# MCXC444 register map
Vendor: NXP Semiconductors; Series: MCX; File version: 1.6
CPU: CM0PLUS r0p0, little endian, no MPU, no FPU, VTOR, 2 interrupt priority bits
Registers are 32-bit, read-write, reset 0x0 unless marked. A register's access mark holds for its fields unless they carry their own. Offsets are from the block's base; [hi:lo] are bit positions; {n}, {i} and the like mark numbered series; 'fields as' and 'values as' point back to an identical list.

## LCD — Segment Liquid Crystal Display
Base 0x40053000; register names take the prefix LCD_
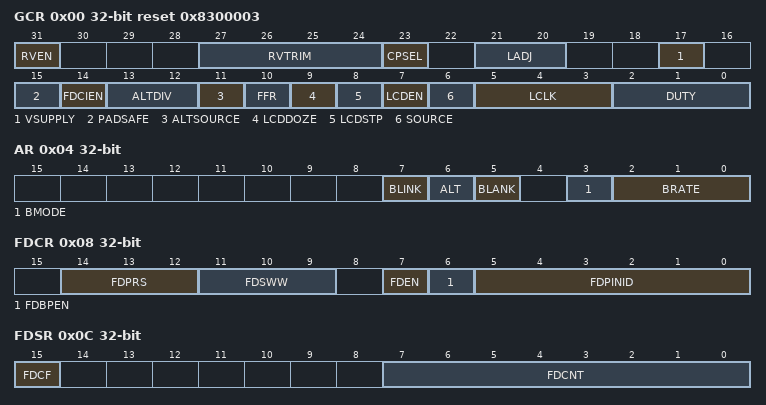
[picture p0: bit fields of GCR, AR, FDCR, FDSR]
0x00 GCR reset 0x8300003 — LCD General Control Register
  [31] RVEN — Regulated Voltage Enable
    0=b0 (Regulated voltage disabled.); 1=b1 (Regulated voltage enabled.)
  [27:24] RVTRIM — Regulated Voltage Trim
  [23] CPSEL — Charge Pump or Resistor Bias Select
    0=b0 (LCD charge pump is disabled. Resistor network selected. (The internal 1/3-bias is forced.)); 1=b1 (LCD charge pump is selected. Resistor network disabled. (The internal 1/3-bias is forced.))
  [21:20] LADJ — Load Adjust
  [17] VSUPPLY — Voltage Supply Control
    0=b0 (Drive VLL3 internally from VDD); 1=b1 (Drive VLL3 externally from VDD or drive VLL internally from vIREG)
  [15] PADSAFE — Pad Safe State Enable
    0=b0 (LCD frontplane and backplane functions enabled according to other LCD control bits); 1=b1 (LCD frontplane and backplane functions disabled)
  [14] FDCIEN — LCD Fault Detection Complete Interrupt Enable
    0=b0 (No interrupt request is generated by this event.); 1=b1 (When a fault is detected and FDCF bit is set, this event causes an interrupt request.)
  [13:12] ALTDIV — LCD AlternateClock Divider
    0=b00 (Divide factor = 1 (No divide)); 1=b01 (Divide factor = 8); 2=b10 (Divide factor = 64); 3=b11 (Divide factor = 512)
  [11] ALTSOURCE — Selects the alternate clock source
    0=b0 (Select Alternate Clock Source 1 (default)); 1=b1 (Select Alternate Clock Source 2)
  [10] FFR — Fast Frame Rate Select
    0=b0 (Standard Frame Rate LCD Frame Freq: 23.3 (min) 73.1 (max)); 1=b1 (Fast Frame Rate (Standard Frame Rate x2) LCD Frame Freq: 46.6 (min) 146.2 (max))
  [9] LCDDOZE — LCD Doze enable
    0=b0 (Allows the LCD driver, charge pump, resistor bias network, and voltage regulator to continue running during Doze mode.); 1=b1 (Disables the LCD driver, charge pump, resistor bias network, and voltage regulator when MCU enters Doze mode.)
  [8] LCDSTP — LCD Stop
    0=b0 (Allows the LCD driver, charge pump, resistor bias network, and voltage regulator to continue running during Stop mode.); 1=b1 (Disables the LCD driver, charge pump, resistor bias network, and voltage regulator when MCU enters Stop mode.)
  [7] LCDEN — LCD Driver Enable
    0=b0 (All front plane and back plane pins are disabled. The LCD controller system is also disabled, and all LCD waveform generation clocks are stopped. V LL3 is connected to V DD internally. All LCD pins, LCD_Pn, enabled using the LCD Pin Enable register, output a low value.); 1=b1 (LCD controller driver system is enabled, and front plane and back plane waveforms are generated. All LCD pins, LCD_Pn, enabled if PAD_SAFE is clearusing the LCD Pin Enable register, output an LCD driver waveform. The back plane pins output an LCD driver back plane waveform based on the settings of DUTY[2:0]. Charge pump or resistor bias is enabled.)
  [6] SOURCE — LCD Clock Source Select
    0=b0 (Selects the default clock as the LCD clock source.); 1=b1 (Selects output of the alternate clock source selection (see ALTSOURCE) as the LCD clock source.)
  [5:3] LCLK — LCD Clock Prescaler
  [2:0] DUTY — LCD duty select
    0=b000 (Use 1 BP (1/1 duty cycle).); 1=b001 (Use 2 BP (1/2 duty cycle).); 2=b010 (Use 3 BP (1/3 duty cycle).); 3=b011 (Use 4 BP (1/4 duty cycle). (Default)); 7=b111 (Use 8 BP (1/8 duty cycle).)
0x04 AR — LCD Auxiliary Register
  [7] BLINK — Blink command
    0=b0 (Disables blinking.); 1=b1 (Starts blinking at blinking frequency specified by LCD blink rate calculation.)
  [6] ALT — Alternate display mode
    0=b0 (Normal display mode.); 1=b1 (Alternate display mode.)
  [5] BLANK — Blank display mode
    0=b0 (Normal or alternate display mode.); 1=b1 (Blank display mode.)
  [3] BMODE — Blink mode
    0=b0 (Display blank during the blink period.); 1=b1 (Display alternate display during blink period (Ignored if duty is 5 or greater).)
  [2:0] BRATE — Blink-rate configuration
0x08 FDCR — LCD Fault Detect Control Register
  [14:12] FDPRS — Fault Detect Clock Prescaler
    0=b000 (1/1 bus clock.); 1=b001 (1/2 bus clock.); 2=b010 (1/4 bus clock.); 3=b011 (1/8 bus clock.); 4=b100 (1/16 bus clock.); 5=b101 (1/32 bus clock.); 6=b110 (1/64 bus clock.); 7=b111 (1/128 bus clock.)
  [11:9] FDSWW — Fault Detect Sample Window Width
    0=b000 (Sample window width is 4 sample clock cycles.); 1=b001 (Sample window width is 8 sample clock cycles.); 2=b010 (Sample window width is 16 sample clock cycles.); 3=b011 (Sample window width is 32 sample clock cycles.); 4=b100 (Sample window width is 64 sample clock cycles.); 5=b101 (Sample window width is 128 sample clock cycles.); 6=b110 (Sample window width is 256 sample clock cycles.); 7=b111 (Sample window width is 512 sample clock cycles.)
  [7] FDEN — Fault Detect Enable
    0=b0 (Disable fault detection.); 1=b1 (Enable fault detection.)
  [6] FDBPEN — Fault Detect Back Plane Enable
    0=b0 (Type of the selected pin under fault detect test is front plane.); 1=b1 (Type of the selected pin under fault detect test is back plane.)
  [5:0] FDPINID — Fault Detect Pin ID
    0=b000000 (Fault detection for LCD_P0 pin.); 1=b000001 (Fault detection for LCD_P1 pin.); 63=b111111 (Fault detection for LCD_P63 pin.)
0x0C FDSR — LCD Fault Detect Status Register
  [15] FDCF — Fault Detection Complete Flag
    0=b0 (Fault detection is not completed.); 1=b1 (Fault detection is completed.)
  [7:0] FDCNT ro — Fault Detect Counter
    0=b00000000 (No "one" samples.); 1=b00000001 (1 "one" samples.); 2=b00000010 (2 "one" samples.); 254=b11111110 (254 "one" samples.); 255=b11111111 (255 or more "one" samples. The FDCNT can overflow. Therefore, FDSWW and FDPRS must be reconfigured for proper sampling.)
0x10 PEN{x} (x=L,H; step 0x4) — LCD Pin Enable register
  [31:0] PEN — LCD Pin Enable
    0=b00000000000000000000000000000000 (LCD operation disabled on LCD_Pn.); 1=b00000000000000000000000000000001 (LCD operation enabled on LCD_Pn.)
0x18 BPEN{x} (x=L,H; step 0x4) — LCD Back Plane Enable register
  [31:0] BPEN — Back Plane Enable
    0=b00000000000000000000000000000000 (Front plane operation enabled on LCD_Pn.); 1=b00000000000000000000000000000001 (Back plane operation enabled on LCD_Pn.)
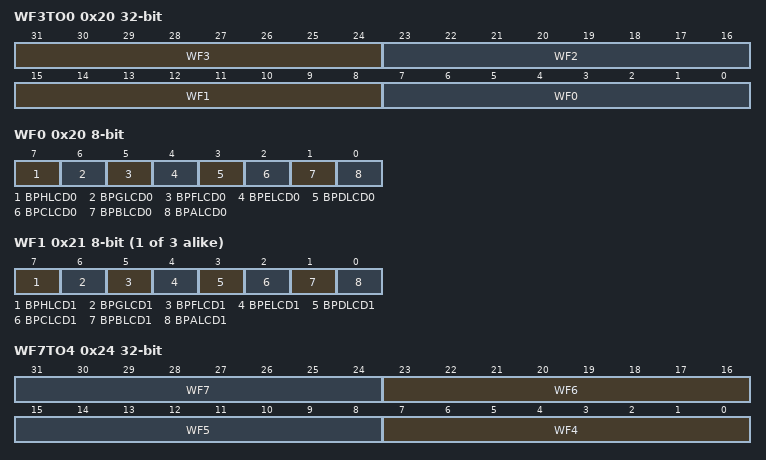
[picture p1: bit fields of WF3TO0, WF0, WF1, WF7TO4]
0x20 WF3TO0 (LCD view) — LCD Waveform register
  [31:24] WF3 — Segment-on front plane operation - Each bit turns on or off the segments associated with LCD_P3 in the following pattern: HGFEDCBA (most significant bit controls segment H and least significant bit controls segment A)
  [23:16] WF2 — Controls segments or phases connected to LCD_P2 as described above for WF3.
  [15:8] WF1 — Controls segments or phases connected to LCD_P1 as described above for WF3.
  [7:0] WF0 — Controls segments or phases connected to LCD_P0 as described above for WF3.
0x20 WF0 8-bit reset not defined (LCD view) — LCD Waveform Register 0.
  [7] BPHLCD0
    0=b0 (LCD segment off or LCD backplane inactive for phase H); 1=b1 (LCD segment on or LCD backplane active for phase H)
  [6] BPGLCD0
    0=b0 (LCD segment off or LCD backplane inactive for phase G); 1=b1 (LCD segment on or LCD backplane active for phase G)
  [5] BPFLCD0
    0=b0 (LCD segment off or LCD backplane inactive for phase F); 1=b1 (LCD segment on or LCD backplane active for phase F)
  [4] BPELCD0
    0=b0 (LCD segment off or LCD backplane inactive for phase E); 1=b1 (LCD segment on or LCD backplane active for phase E)
  [3] BPDLCD0
    0=b0 (LCD segment off or LCD backplane inactive for phase D); 1=b1 (LCD segment on or LCD backplane active for phase D)
  [2] BPCLCD0
    0=b0 (LCD segment off or LCD backplane inactive for phase C); 1=b1 (LCD segment on or LCD backplane active for phase C)
  [1] BPBLCD0
    0=b0 (LCD segment off or LCD backplane inactive for phase B); 1=b1 (LCD segment on or LCD backplane active for phase B)
  [0] BPALCD0
    0=b0 (LCD segment off or LCD backplane inactive for phase A); 1=b1 (LCD segment on or LCD backplane active for phase A)
{0x20+i} WF{i} 8-bit reset not defined (i=1..3) — LCD Waveform Register {i}.
  [7] BPHLCD{i}
    values as WF0.BPHLCD0
  [6] BPGLCD{i}
    values as WF0.BPGLCD0
  [5] BPFLCD{i}
    values as WF0.BPFLCD0
  [4] BPELCD{i}
    values as WF0.BPELCD0
  [3] BPDLCD{i}
    values as WF0.BPDLCD0
  [2] BPCLCD{i}
    values as WF0.BPCLCD0
  [1] BPBLCD{i}
    values as WF0.BPBLCD0
  [0] BPALCD{i}
    values as WF0.BPALCD0
0x24 WF7TO4 (LCD view) — LCD Waveform register
  [8n-25:8n-32] WF{n} (n=4..7) — Controls segments or phases connected to LCD_P{n} as described above for WF3TO0[WF3].
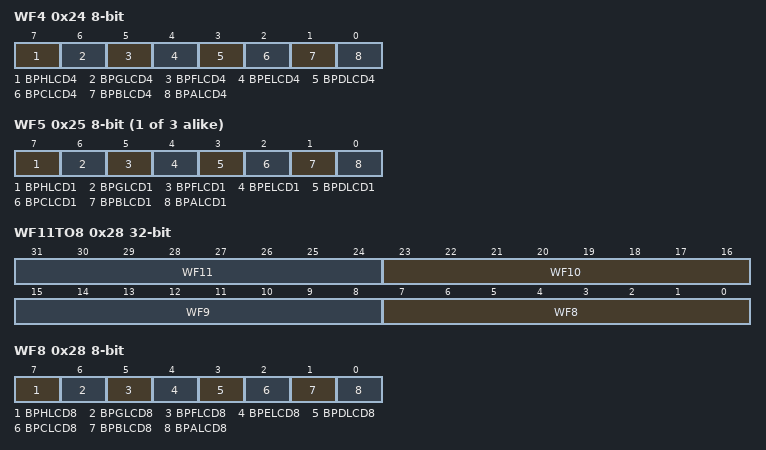
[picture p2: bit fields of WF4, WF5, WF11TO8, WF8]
0x24 WF4 8-bit reset not defined (LCD view) — LCD Waveform Register 4.
  [7] BPHLCD4
    values as WF0.BPHLCD0
  [6] BPGLCD4
    values as WF0.BPGLCD0
  [5] BPFLCD4
    values as WF0.BPFLCD0
  [4] BPELCD4
    values as WF0.BPELCD0
  [3] BPDLCD4
    values as WF0.BPDLCD0
  [2] BPCLCD4
    values as WF0.BPCLCD0
  [1] BPBLCD4
    values as WF0.BPBLCD0
  [0] BPALCD4
    values as WF0.BPALCD0
{0x20+i} WF{i} 8-bit reset not defined (i=5..7) — LCD Waveform Register {i}.
  fields as WF1
0x28 WF11TO8 (LCD view) — LCD Waveform register
  [8n-57:8n-64] WF{n} (n=8..11) — Controls segments or phases connected to LCD_P{n} as described above for WF3TO0[WF3].
0x28 WF8 8-bit reset not defined (LCD view) — LCD Waveform Register 8.
  [7] BPHLCD8
    values as WF0.BPHLCD0
  [6] BPGLCD8
    values as WF0.BPGLCD0
  [5] BPFLCD8
    values as WF0.BPFLCD0
  [4] BPELCD8
    values as WF0.BPELCD0
  [3] BPDLCD8
    values as WF0.BPDLCD0
  [2] BPCLCD8
    values as WF0.BPCLCD0
  [1] BPBLCD8
    values as WF0.BPBLCD0
  [0] BPALCD8
    values as WF0.BPALCD0
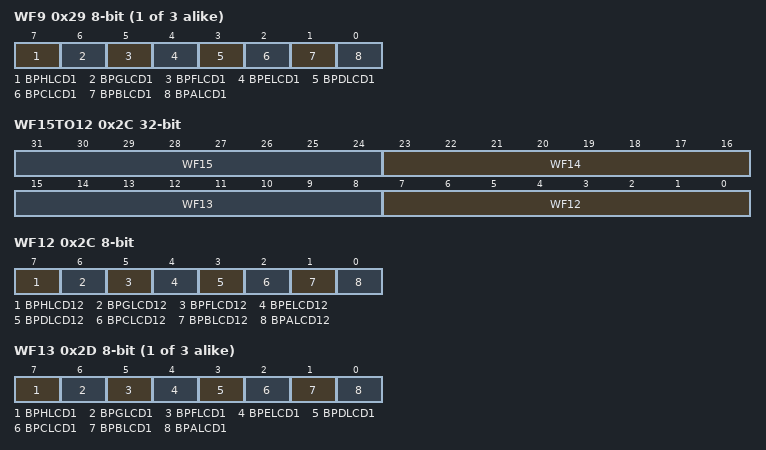
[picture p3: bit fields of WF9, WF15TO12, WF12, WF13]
{0x20+i} WF{i} 8-bit reset not defined (i=9..11) — LCD Waveform Register {i}.
  fields as WF1
0x2C WF15TO12 (LCD view) — LCD Waveform register
  [8n-89:8n-96] WF{n} (n=12..15) — Controls segments or phases connected to LCD_P{n} as described above for WF3TO0[WF3].
0x2C WF12 8-bit reset not defined (LCD view) — LCD Waveform Register 12.
  [7] BPHLCD12
    values as WF0.BPHLCD0
  [6] BPGLCD12
    values as WF0.BPGLCD0
  [5] BPFLCD12
    values as WF0.BPFLCD0
  [4] BPELCD12
    values as WF0.BPELCD0
  [3] BPDLCD12
    values as WF0.BPDLCD0
  [2] BPCLCD12
    values as WF0.BPCLCD0
  [1] BPBLCD12
    values as WF0.BPBLCD0
  [0] BPALCD12
    values as WF0.BPALCD0
{0x20+i} WF{i} 8-bit reset not defined (i=13..15) — LCD Waveform Register {i}.
  fields as WF1
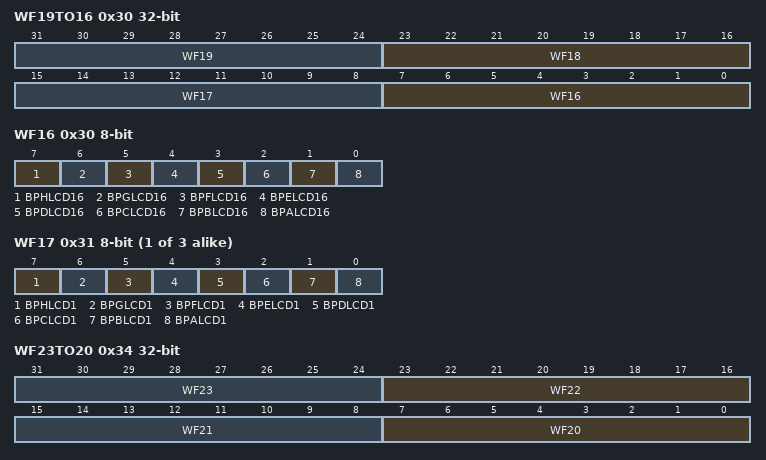
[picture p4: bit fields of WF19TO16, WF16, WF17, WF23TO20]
0x30 WF19TO16 (LCD view) — LCD Waveform register
  [8n-121:8n-128] WF{n} (n=16..19) — Controls segments or phases connected to LCD_P{n} as described above for WF3TO0[WF3].
0x30 WF16 8-bit reset not defined (LCD view) — LCD Waveform Register 16.
  [7] BPHLCD16
    values as WF0.BPHLCD0
  [6] BPGLCD16
    values as WF0.BPGLCD0
  [5] BPFLCD16
    values as WF0.BPFLCD0
  [4] BPELCD16
    values as WF0.BPELCD0
  [3] BPDLCD16
    values as WF0.BPDLCD0
  [2] BPCLCD16
    values as WF0.BPCLCD0
  [1] BPBLCD16
    values as WF0.BPBLCD0
  [0] BPALCD16
    values as WF0.BPALCD0
{0x20+i} WF{i} 8-bit reset not defined (i=17..19) — LCD Waveform Register {i}.
  fields as WF1
0x34 WF23TO20 (LCD view) — LCD Waveform register
  [8n-153:8n-160] WF{n} (n=20..23) — Controls segments or phases connected to LCD_P{n} as described above for WF3TO0[WF3].
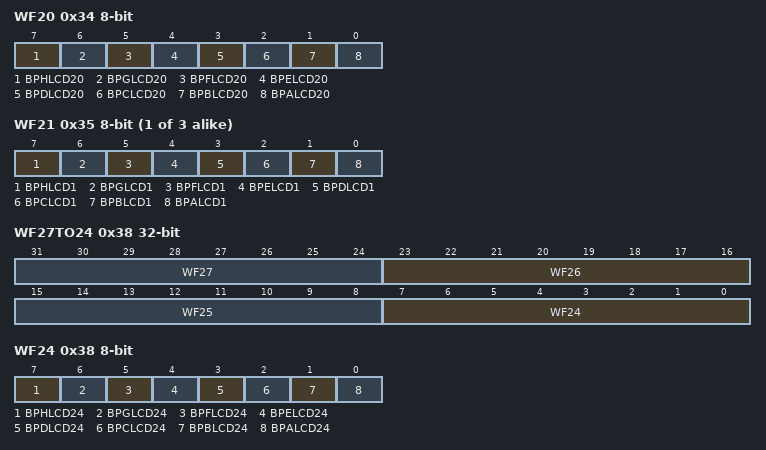
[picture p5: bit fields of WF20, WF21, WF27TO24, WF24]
0x34 WF20 8-bit reset not defined (LCD view) — LCD Waveform Register 20.
  [7] BPHLCD20
    values as WF0.BPHLCD0
  [6] BPGLCD20
    values as WF0.BPGLCD0
  [5] BPFLCD20
    values as WF0.BPFLCD0
  [4] BPELCD20
    values as WF0.BPELCD0
  [3] BPDLCD20
    values as WF0.BPDLCD0
  [2] BPCLCD20
    values as WF0.BPCLCD0
  [1] BPBLCD20
    values as WF0.BPBLCD0
  [0] BPALCD20
    values as WF0.BPALCD0
{0x20+i} WF{i} 8-bit reset not defined (i=21..23) — LCD Waveform Register {i}.
  fields as WF1
0x38 WF27TO24 (LCD view) — LCD Waveform register
  [8n-185:8n-192] WF{n} (n=24..27) — Controls segments or phases connected to LCD_P{n} as described above for WF3TO0[WF3].
0x38 WF24 8-bit reset not defined (LCD view) — LCD Waveform Register 24.
  [7] BPHLCD24
    values as WF0.BPHLCD0
  [6] BPGLCD24
    values as WF0.BPGLCD0
  [5] BPFLCD24
    values as WF0.BPFLCD0
  [4] BPELCD24
    values as WF0.BPELCD0
  [3] BPDLCD24
    values as WF0.BPDLCD0
  [2] BPCLCD24
    values as WF0.BPCLCD0
  [1] BPBLCD24
    values as WF0.BPBLCD0
  [0] BPALCD24
    values as WF0.BPALCD0
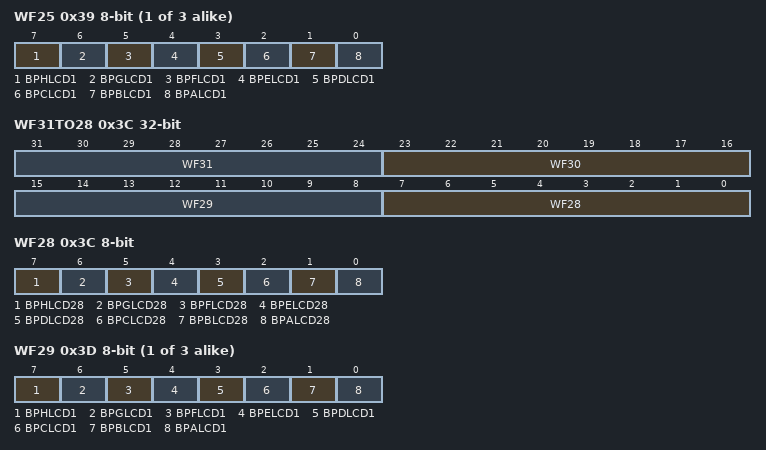
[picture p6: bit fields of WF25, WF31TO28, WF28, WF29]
{0x20+i} WF{i} 8-bit reset not defined (i=25..27) — LCD Waveform Register {i}.
  fields as WF1
0x3C WF31TO28 (LCD view) — LCD Waveform register
  [8n-217:8n-224] WF{n} (n=28..31) — Controls segments or phases connected to LCD_P{n} as described above for WF3TO0[WF3].
0x3C WF28 8-bit reset not defined (LCD view) — LCD Waveform Register 28.
  [7] BPHLCD28
    values as WF0.BPHLCD0
  [6] BPGLCD28
    values as WF0.BPGLCD0
  [5] BPFLCD28
    values as WF0.BPFLCD0
  [4] BPELCD28
    values as WF0.BPELCD0
  [3] BPDLCD28
    values as WF0.BPDLCD0
  [2] BPCLCD28
    values as WF0.BPCLCD0
  [1] BPBLCD28
    values as WF0.BPBLCD0
  [0] BPALCD28
    values as WF0.BPALCD0
{0x20+i} WF{i} 8-bit reset not defined (i=29..31) — LCD Waveform Register {i}.
  fields as WF1
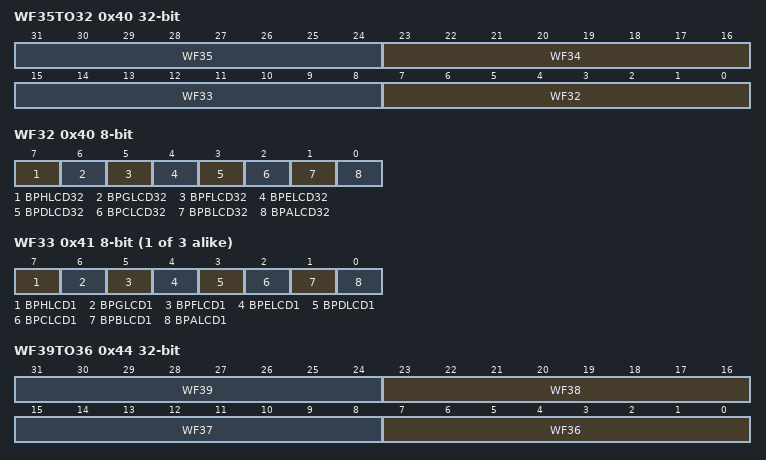
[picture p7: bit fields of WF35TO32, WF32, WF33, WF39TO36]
0x40 WF35TO32 (LCD view) — LCD Waveform register
  [8n-249:8n-256] WF{n} (n=32..35) — Controls segments or phases connected to LCD_P{n} as described above for WF3TO0[WF3].
0x40 WF32 8-bit reset not defined (LCD view) — LCD Waveform Register 32.
  [7] BPHLCD32
    values as WF0.BPHLCD0
  [6] BPGLCD32
    values as WF0.BPGLCD0
  [5] BPFLCD32
    values as WF0.BPFLCD0
  [4] BPELCD32
    values as WF0.BPELCD0
  [3] BPDLCD32
    values as WF0.BPDLCD0
  [2] BPCLCD32
    values as WF0.BPCLCD0
  [1] BPBLCD32
    values as WF0.BPBLCD0
  [0] BPALCD32
    values as WF0.BPALCD0
{0x20+i} WF{i} 8-bit reset not defined (i=33..35) — LCD Waveform Register {i}.
  fields as WF1
0x44 WF39TO36 (LCD view) — LCD Waveform register
  [8n-281:8n-288] WF{n} (n=36..39) — Controls segments or phases connected to LCD_P{n} as described above for WF3TO0[WF3].
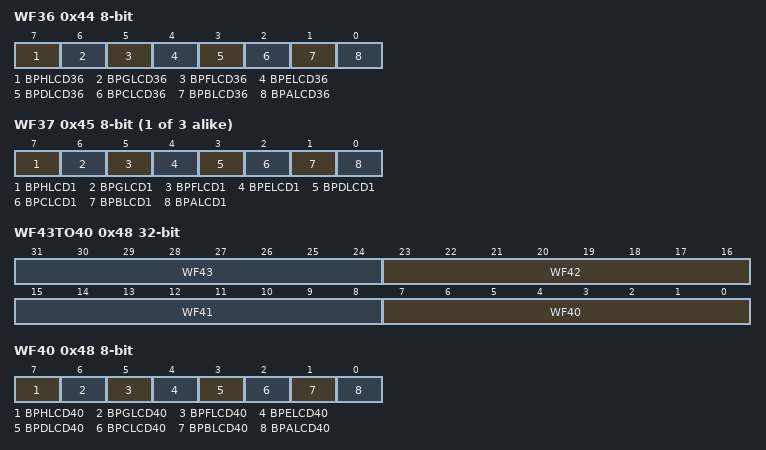
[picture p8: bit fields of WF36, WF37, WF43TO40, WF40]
0x44 WF36 8-bit reset not defined (LCD view) — LCD Waveform Register 36.
  [7] BPHLCD36
    values as WF0.BPHLCD0
  [6] BPGLCD36
    values as WF0.BPGLCD0
  [5] BPFLCD36
    values as WF0.BPFLCD0
  [4] BPELCD36
    values as WF0.BPELCD0
  [3] BPDLCD36
    values as WF0.BPDLCD0
  [2] BPCLCD36
    values as WF0.BPCLCD0
  [1] BPBLCD36
    values as WF0.BPBLCD0
  [0] BPALCD36
    values as WF0.BPALCD0
{0x20+i} WF{i} 8-bit reset not defined (i=37..39) — LCD Waveform Register {i}.
  fields as WF1
0x48 WF43TO40 (LCD view) — LCD Waveform register
  [8n-313:8n-320] WF{n} (n=40..43) — Controls segments or phases connected to LCD_P{n} as described above for WF3TO0[WF3].
0x48 WF40 8-bit reset not defined (LCD view) — LCD Waveform Register 40.
  [7] BPHLCD40
    values as WF0.BPHLCD0
  [6] BPGLCD40
    values as WF0.BPGLCD0
  [5] BPFLCD40
    values as WF0.BPFLCD0
  [4] BPELCD40
    values as WF0.BPELCD0
  [3] BPDLCD40
    values as WF0.BPDLCD0
  [2] BPCLCD40
    values as WF0.BPCLCD0
  [1] BPBLCD40
    values as WF0.BPBLCD0
  [0] BPALCD40
    values as WF0.BPALCD0
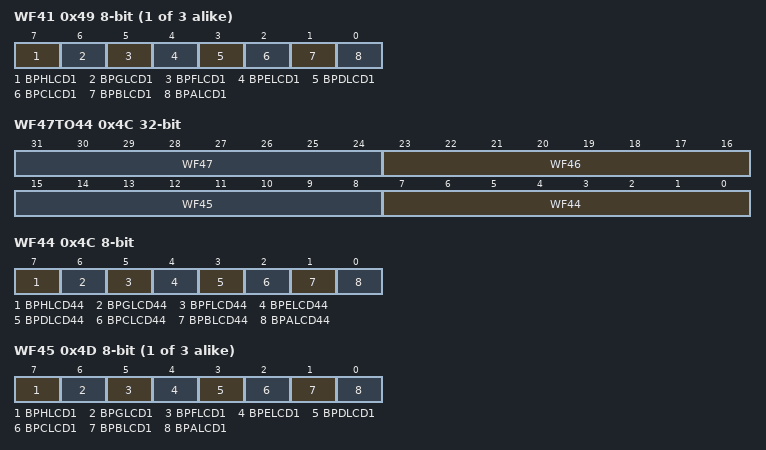
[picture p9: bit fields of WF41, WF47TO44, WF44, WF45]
{0x20+i} WF{i} 8-bit reset not defined (i=41..43) — LCD Waveform Register {i}.
  fields as WF1
0x4C WF47TO44 (LCD view) — LCD Waveform register
  [8n-345:8n-352] WF{n} (n=44..47) — Controls segments or phases connected to LCD_P{n} as described above for WF3TO0[WF3].
0x4C WF44 8-bit reset not defined (LCD view) — LCD Waveform Register 44.
  [7] BPHLCD44
    values as WF0.BPHLCD0
  [6] BPGLCD44
    values as WF0.BPGLCD0
  [5] BPFLCD44
    values as WF0.BPFLCD0
  [4] BPELCD44
    values as WF0.BPELCD0
  [3] BPDLCD44
    values as WF0.BPDLCD0
  [2] BPCLCD44
    values as WF0.BPCLCD0
  [1] BPBLCD44
    values as WF0.BPBLCD0
  [0] BPALCD44
    values as WF0.BPALCD0
{0x20+i} WF{i} 8-bit reset not defined (i=45..47) — LCD Waveform Register {i}.
  fields as WF1
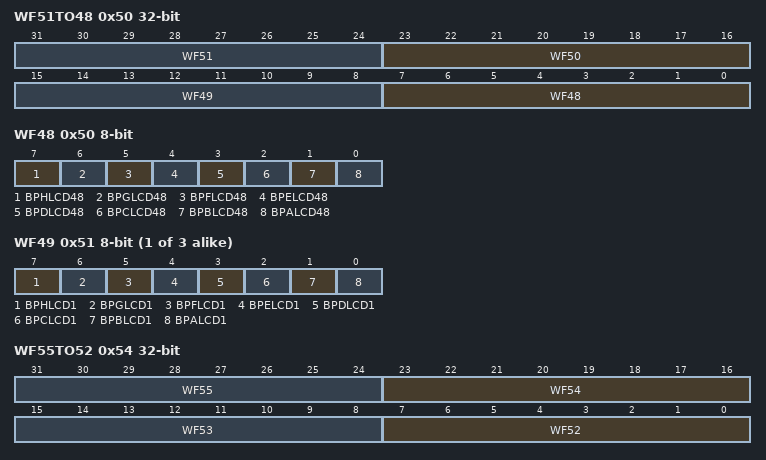
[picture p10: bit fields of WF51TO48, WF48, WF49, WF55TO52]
0x50 WF51TO48 (LCD view) — LCD Waveform register
  [8n-377:8n-384] WF{n} (n=48..51) — Controls segments or phases connected to LCD_P{n} as described above for WF3TO0[WF3].
0x50 WF48 8-bit reset not defined (LCD view) — LCD Waveform Register 48.
  [7] BPHLCD48
    values as WF0.BPHLCD0
  [6] BPGLCD48
    values as WF0.BPGLCD0
  [5] BPFLCD48
    values as WF0.BPFLCD0
  [4] BPELCD48
    values as WF0.BPELCD0
  [3] BPDLCD48
    values as WF0.BPDLCD0
  [2] BPCLCD48
    values as WF0.BPCLCD0
  [1] BPBLCD48
    values as WF0.BPBLCD0
  [0] BPALCD48
    values as WF0.BPALCD0
{0x20+i} WF{i} 8-bit reset not defined (i=49..51) — LCD Waveform Register {i}.
  fields as WF1
0x54 WF55TO52 (LCD view) — LCD Waveform register
  [8n-409:8n-416] WF{n} (n=52..55) — Controls segments or phases connected to LCD_P{n} as described above for WF3TO0[WF3].
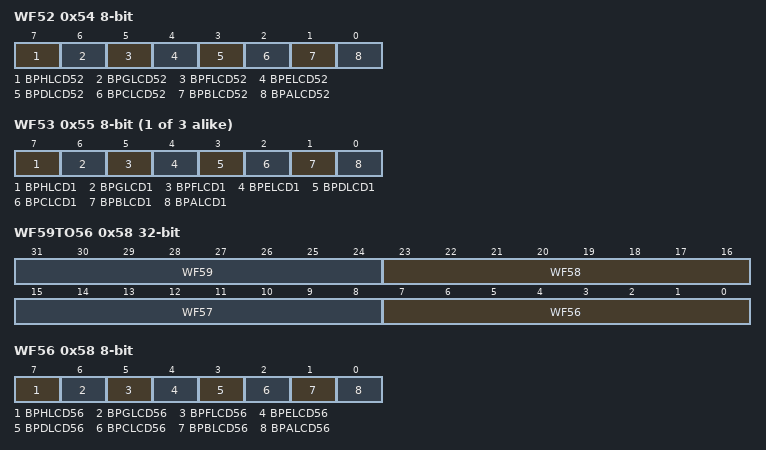
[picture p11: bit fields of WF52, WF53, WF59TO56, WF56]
0x54 WF52 8-bit reset not defined (LCD view) — LCD Waveform Register 52.
  [7] BPHLCD52
    values as WF0.BPHLCD0
  [6] BPGLCD52
    values as WF0.BPGLCD0
  [5] BPFLCD52
    values as WF0.BPFLCD0
  [4] BPELCD52
    values as WF0.BPELCD0
  [3] BPDLCD52
    values as WF0.BPDLCD0
  [2] BPCLCD52
    values as WF0.BPCLCD0
  [1] BPBLCD52
    values as WF0.BPBLCD0
  [0] BPALCD52
    values as WF0.BPALCD0
{0x20+i} WF{i} 8-bit reset not defined (i=53..55) — LCD Waveform Register {i}.
  fields as WF1
0x58 WF59TO56 (LCD view) — LCD Waveform register
  [8n-441:8n-448] WF{n} (n=56..59) — Controls segments or phases connected to LCD_P{n} as described above for WF3TO0[WF3].
0x58 WF56 8-bit reset not defined (LCD view) — LCD Waveform Register 56.
  [7] BPHLCD56
    values as WF0.BPHLCD0
  [6] BPGLCD56
    values as WF0.BPGLCD0
  [5] BPFLCD56
    values as WF0.BPFLCD0
  [4] BPELCD56
    values as WF0.BPELCD0
  [3] BPDLCD56
    values as WF0.BPDLCD0
  [2] BPCLCD56
    values as WF0.BPCLCD0
  [1] BPBLCD56
    values as WF0.BPBLCD0
  [0] BPALCD56
    values as WF0.BPALCD0
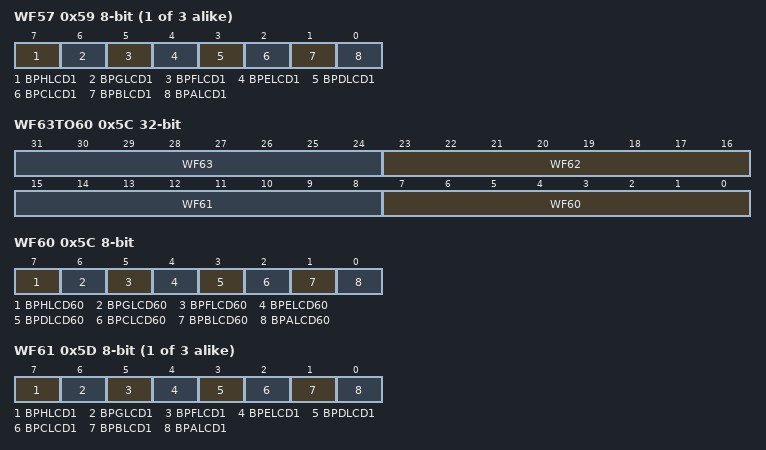
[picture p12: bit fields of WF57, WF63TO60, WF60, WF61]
{0x20+i} WF{i} 8-bit reset not defined (i=57..59) — LCD Waveform Register {i}.
  fields as WF1
0x5C WF63TO60 (LCD view) — LCD Waveform register
  [8n-473:8n-480] WF{n} (n=60..63) — Controls segments or phases connected to LCD_P{n} as described above for WF3TO0[WF3].
0x5C WF60 8-bit reset not defined (LCD view) — LCD Waveform Register 60.
  [7] BPHLCD60
    values as WF0.BPHLCD0
  [6] BPGLCD60
    values as WF0.BPGLCD0
  [5] BPFLCD60
    values as WF0.BPFLCD0
  [4] BPELCD60
    values as WF0.BPELCD0
  [3] BPDLCD60
    values as WF0.BPDLCD0
  [2] BPCLCD60
    values as WF0.BPCLCD0
  [1] BPBLCD60
    values as WF0.BPBLCD0
  [0] BPALCD60
    values as WF0.BPALCD0
{0x20+i} WF{i} 8-bit reset not defined (i=61..63) — LCD Waveform Register {i}.
  fields as WF1
